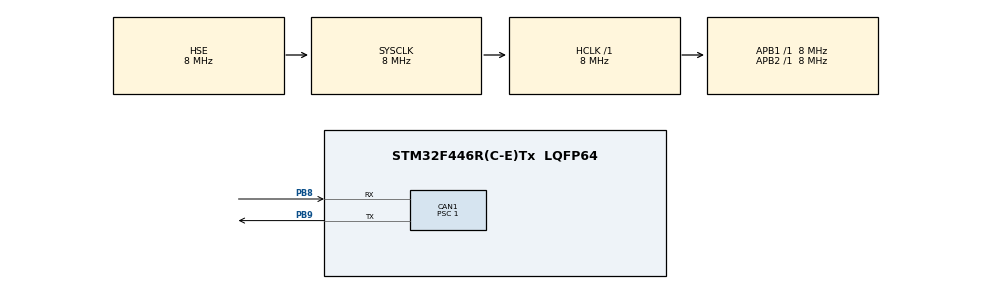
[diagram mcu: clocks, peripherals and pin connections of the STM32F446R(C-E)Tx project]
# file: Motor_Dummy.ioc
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CAN1.ABOM=ENABLE
CAN1.BS1=CAN_BS1_13TQ
CAN1.BS2=CAN_BS2_2TQ
CAN1.CalculateBaudRate=500000
CAN1.CalculateTimeBit=2000
CAN1.CalculateTimeQuantum=125.0
CAN1.NART=ENABLE
CAN1.Prescaler=1
Mcu.Family=STM32F4
Mcu.Name=STM32F446R(C-E)Tx
Mcu.Package=LQFP64
NVIC.PriorityGroup=NVIC_PRIORITYGROUP_4
PB8.Mode=CAN_Activate
PB8.Signal=CAN1_RX
PB9.Mode=CAN_Activate
PB9.Signal=CAN1_TX
PH0-OSC_IN.Mode=HSE-External-Oscillator
PH0-OSC_IN.Signal=RCC_OSC_IN
PH1-OSC_OUT.Mode=HSE-External-Oscillator
PH1-OSC_OUT.Signal=RCC_OSC_OUT
ProjectManager.HeapSize=0x200
ProjectManager.StackSize=0x400
ProjectManager.TargetToolchain=STM32CubeIDE
RCC.AHBFreq_Value=8000000
RCC.APB1CLKDivider=RCC_HCLK_DIV1
RCC.APB1Freq_Value=8000000
RCC.APB1TimFreq_Value=8000000
RCC.APB2CLKDivider=RCC_HCLK_DIV1
RCC.APB2Freq_Value=8000000
RCC.APB2TimFreq_Value=8000000
RCC.CortexFreq_Value=8000000
RCC.HCLKFreq_Value=8000000
RCC.HSE_VALUE=8000000
RCC.SYSCLKFreq_VALUE=8000000
RCC.SYSCLKSource=RCC_SYSCLKSOURCE_HSE
RCC.USBFreq_Value=96000000
RCC.VCOOutputFreq_Value=192000000
board=custom

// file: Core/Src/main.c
/* USER CODE BEGIN Header */
/**
  ******************************************************************************
  * @file           : main.c
  * @brief          : Main program body
  ******************************************************************************
  * @attention
  *
  * Copyright (c) 2026 STMicroelectronics.
  * All rights reserved.
  *
  * This software is licensed under terms that can be found in the LICENSE file
  * in the root directory of this software component.
  * If no LICENSE file comes with this software, it is provided AS-IS.
  *
  ******************************************************************************
  */
/* USER CODE END Header */
#include "main.h"

/* USER CODE BEGIN Includes */
#include "motor_dummy.h"

/* USER CODE END Includes */

CAN_HandleTypeDef hcan1;

void SystemClock_Config(void);
static void MX_GPIO_Init(void);
static void MX_CAN1_Init(void);

int main(void)
{

  /* MCU Configuration--------------------------------------------------------*/

  /* Reset of all peripherals, Initializes the Flash interface and the Systick. */
  HAL_Init();

  /* Configure the system clock */
  SystemClock_Config();

  /* Initialize all configured peripherals */
  MX_GPIO_Init();
  MX_CAN1_Init();
  /* USER CODE BEGIN 2 */
  if (HAL_CAN_Start(&hcan1) != HAL_OK) { Error_Handler(); }
  Motor_Dummy_Init(&hcan1);

  /* USER CODE END 2 */

  /* Infinite loop */
  while (1)
  {

    /* USER CODE BEGIN 3 */
    Motor_Dummy_Task();
  }
  /* USER CODE END 3 */
}

void SystemClock_Config(void)
{
  RCC_OscInitTypeDef RCC_OscInitStruct = {0};
  RCC_ClkInitTypeDef RCC_ClkInitStruct = {0};

  /** Configure the main internal regulator output voltage
  */
  __HAL_RCC_PWR_CLK_ENABLE();
  __HAL_PWR_VOLTAGESCALING_CONFIG(PWR_REGULATOR_VOLTAGE_SCALE3);

  /** Initializes the RCC Oscillators according to the specified parameters
  * in the RCC_OscInitTypeDef structure.
  */
  RCC_OscInitStruct.OscillatorType = RCC_OSCILLATORTYPE_HSE;
  RCC_OscInitStruct.HSEState = RCC_HSE_ON;
  RCC_OscInitStruct.PLL.PLLState = RCC_PLL_NONE;
  if (HAL_RCC_OscConfig(&RCC_OscInitStruct) != HAL_OK)
  {
    Error_Handler();
  }

  /** Initializes the CPU, AHB and APB buses clocks
  */
  RCC_ClkInitStruct.ClockType = RCC_CLOCKTYPE_HCLK|RCC_CLOCKTYPE_SYSCLK
                              |RCC_CLOCKTYPE_PCLK1|RCC_CLOCKTYPE_PCLK2;
  RCC_ClkInitStruct.SYSCLKSource = RCC_SYSCLKSOURCE_HSE;
  RCC_ClkInitStruct.AHBCLKDivider = RCC_SYSCLK_DIV1;
  RCC_ClkInitStruct.APB1CLKDivider = RCC_HCLK_DIV1;
  RCC_ClkInitStruct.APB2CLKDivider = RCC_HCLK_DIV1;

  if (HAL_RCC_ClockConfig(&RCC_ClkInitStruct, FLASH_LATENCY_0) != HAL_OK)
  {
    Error_Handler();
  }
}

static void MX_CAN1_Init(void)
{

  hcan1.Instance = CAN1;
  hcan1.Init.Prescaler = 1;
  hcan1.Init.Mode = CAN_MODE_NORMAL;
  hcan1.Init.SyncJumpWidth = CAN_SJW_1TQ;
  hcan1.Init.TimeSeg1 = CAN_BS1_13TQ;
  hcan1.Init.TimeSeg2 = CAN_BS2_2TQ;
  hcan1.Init.TimeTriggeredMode = DISABLE;
  hcan1.Init.AutoBusOff = ENABLE;
  hcan1.Init.AutoWakeUp = DISABLE;
  hcan1.Init.AutoRetransmission = ENABLE;
  hcan1.Init.ReceiveFifoLocked = DISABLE;
  hcan1.Init.TransmitFifoPriority = DISABLE;
  if (HAL_CAN_Init(&hcan1) != HAL_OK)
  {
    Error_Handler();
  }

}

static void MX_GPIO_Init(void)
{

  /* GPIO Ports Clock Enable */
  __HAL_RCC_GPIOH_CLK_ENABLE();
  __HAL_RCC_GPIOB_CLK_ENABLE();

}

void Error_Handler(void)
{
  /* [2026-08-30] 원래는 __disable_irq() 후 빈 while(1) 이었다. 그 상태로는
     보드가 죽었는지 그냥 조용한 건지 밖에서 구분할 방법이 전혀 없어서,
     HSE 설정 오류로 세 보드가 모두 멈춰 있는 걸 알아채는 데 오래 걸렸다.
     LD2(PA5)를 빠르게 깜빡여 "펌웨어가 죽었다"를 눈으로 알 수 있게 한다.

     클럭 설정 실패 시점에도 동작해야 하므로 HAL 을 쓰지 않고 레지스터를
     직접 건드린다. 이때 SYSCLK 는 HSI 16 MHz 이므로 아래 지연 상수는
     대략 0.1 초다(정확할 필요 없음). */
  __disable_irq();

  RCC->AHB1ENR |= RCC_AHB1ENR_GPIOAEN;
  (void)RCC->AHB1ENR;                 /* 클럭 인가 반영 대기 */
  GPIOA->MODER   = (GPIOA->MODER & ~(3UL << (5 * 2))) | (1UL << (5 * 2));
  GPIOA->OTYPER &= ~(1UL << 5);

  while (1)
  {
    GPIOA->ODR ^= (1UL << 5);
    for (volatile uint32_t i = 0; i < 200000UL; i++) { __NOP(); }
  }
}
